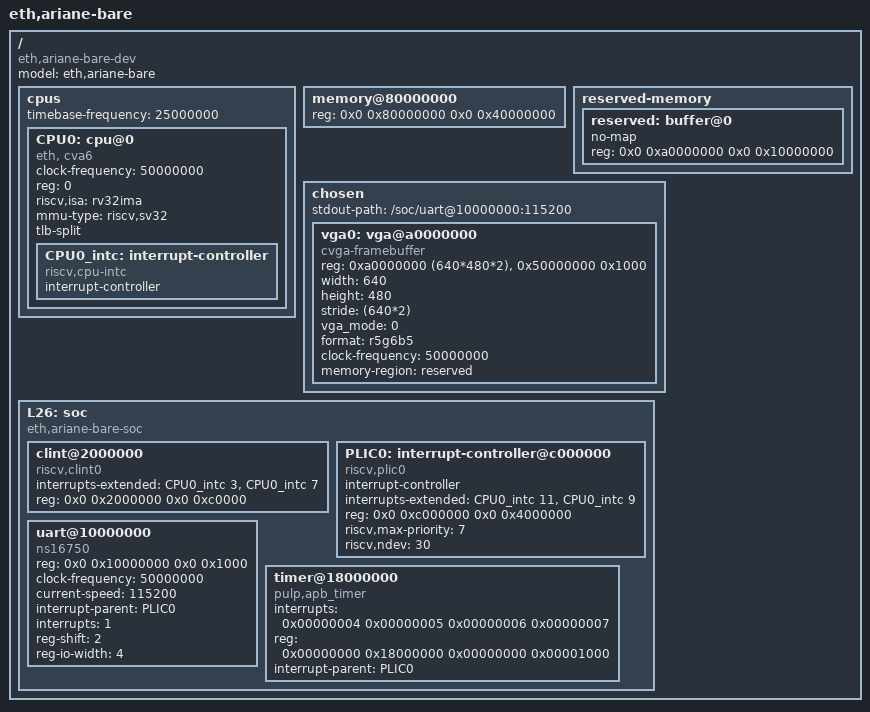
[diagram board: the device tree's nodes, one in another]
/dts-v1/;

/ {
  #address-cells = <2>;
  #size-cells = <2>;
  compatible = "eth,ariane-bare-dev";
  model = "eth,ariane-bare";
  cpus {
    #address-cells = <1>;
    #size-cells = <0>;
    timebase-frequency = <25000000>; // 25 MHz
    CPU0: cpu@0 {
      clock-frequency = <50000000>; // 50 MHz
      device_type = "cpu";
      reg = <0>;
      status = "okay";
      compatible = "eth, cva6", "riscv";
      riscv,isa = "rv32ima";
      mmu-type = "riscv,sv32";
      tlb-split;
      // HLIC - hart local interrupt controller
      CPU0_intc: interrupt-controller {
        #interrupt-cells = <1>;
        interrupt-controller;
        compatible = "riscv,cpu-intc";
      };
    };
  };
  memory@80000000 {
    device_type = "memory";
    reg = <0x0 0x80000000 0x0 0x40000000>;
  };
  reserved-memory {
    #address-cells = <2>;
    #size-cells = <2>;
    ranges;
 
    reserved: buffer@0 {
      no-map;
      reg = <0x0 0xa0000000 0x0 0x10000000>;
    };
  };
  chosen {
    stdout-path = "/soc/uart@10000000:115200";
    #address-cells = <0x1>;
    #size-cells = <0x1>;
    ranges;
    vga0: vga@a0000000 {
      compatible = "cvga-framebuffer";
    
      reg = <0xa0000000 (640*480*2)>, <0x50000000 0x1000>;  width = <640>; height = <480>; stride = <(640*2)>; vga_mode = <0>;
      format = "r5g6b5";
      clock-frequency = <50000000>;
      memory-region = <&reserved>;
    };
  };
  L26: soc {
    #address-cells = <2>;
    #size-cells = <2>;
    compatible = "eth,ariane-bare-soc", "simple-bus";
    ranges;
    clint@2000000 {
      compatible = "riscv,clint0";
      interrupts-extended = <&CPU0_intc 3 &CPU0_intc 7>;
      reg = <0x0 0x2000000 0x0 0xc0000>;
      reg-names = "control";
    };
    PLIC0: interrupt-controller@c000000 {
      #address-cells = <0>;
      #interrupt-cells = <1>;
      compatible = "riscv,plic0";
      interrupt-controller;
      interrupts-extended = <&CPU0_intc 11 &CPU0_intc 9>;
      reg = <0x0 0xc000000 0x0 0x4000000>;
      riscv,max-priority = <7>;
      riscv,ndev = <30>;
    };
    uart@10000000 {
      compatible = "ns16750", "ns16550";
      reg = <0x0 0x10000000 0x0 0x1000>;
      clock-frequency = <50000000>;
      current-speed = <115200>;
      interrupt-parent = <&PLIC0>;
      interrupts = <1>;
      reg-shift = <2>; // regs are spaced on 32 bit boundary
      reg-io-width = <4>; // only 32-bit access are supported
    };
    timer@18000000 {
      compatible = "pulp,apb_timer";
      interrupts = <0x00000004 0x00000005 0x00000006 0x00000007>;
      reg = <0x00000000 0x18000000 0x00000000 0x00001000>;
      interrupt-parent = <&PLIC0>;
      reg-names = "control";
    };
  };
};
